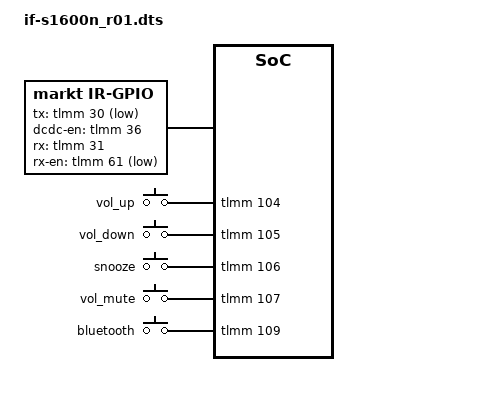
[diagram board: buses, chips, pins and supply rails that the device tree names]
/dts-v1/;

#include "if-s1600n_base.dtsi"

/ {
	markt,board-rev = <0x0001>;
};

&soc {
    ir-gpio {
       compatible = "markt,ir-gpio";
       tx-gpios = <&tlmm 30 GPIO_ACTIVE_LOW>;         
       dcdc-en-gpios = <&tlmm 36 GPIO_ACTIVE_HIGH>;

       rx-gpios = <&tlmm 31 GPIO_ACTIVE_HIGH>;
       rx-en-gpios = <&tlmm 61 GPIO_ACTIVE_LOW>;
       pinctrl-names = "default";
       pinctrl-0 = <&tlmm_ir_gpio_active>;
       status = "ok";
    };
};

&gpio_keys {
    vdd-supply = <&pms405_l12>;
    vdd-voltage = <3300000 3300000>;
    vdd-cureent = <15000>;
    
    vol_up {
        label = "vol_up";
        gpios = <&tlmm 104 GPIO_ACTIVE_HIGH>;
        linux,input-type = <1>;
        linux,code = <KEY_VOLUMEUP>;
        debounce-interval = <50>;
        gpio-key,wakeup;
    };    

    vol_down {
        label = "vol_down";
        gpios = <&tlmm 105 GPIO_ACTIVE_HIGH>;
        linux,input-type = <1>;
        linux,code = <KEY_VOLUMEDOWN>;
        debounce-interval = <50>;
        gpio-key,wakeup;
    };

    snooze {
        label = "snooze";
        gpios = <&tlmm 106 GPIO_ACTIVE_HIGH>;
        linux,input-type = <1>;
        linux,code = <256>;
        debounce-interval = <50>;
        gpio-key,wakeup;
    };

    vol_mute {
        label = "vol_mute";
        gpios = <&tlmm 107 GPIO_ACTIVE_HIGH>;
        linux,input-type = <1>;
        linux,code = <KEY_MUTE>;
        debounce-interval = <50>;
        gpio-key,wakeup;
    };

    bluetooth {
        label = "bluetooth";
        gpios = <&tlmm 109 GPIO_ACTIVE_HIGH>;
        linux,input-type = <1>;
        linux,code = <257>;
        debounce-interval = <50>;
        gpio-key,wakeup;
    };

};


&tlmm {
	evb_tlmm_gpio_key{
		tlmm_gpio_key_active: tlmm_gpio_key_active {
			mux {
				pins = "gpio104", "gpio105", "gpio106", "gpio107", "gpio109";
			};

			config {
				pins = "gpio104", "gpio105", "gpio106", "gpio107", "gpio109";
			drive-strength = <2>;
			bias-disable;
			};
		};

		tlmm_gpio_key_suspend: tlmm_gpio_key_suspend {
			mux {
				pins = "gpio104", "gpio105", "gpio106", "gpio107", "gpio109";
			};

			config {
				pins = "gpio104", "gpio105", "gpio106", "gpio107", "gpio109";
			drive-strength = <2>;
			bias-disable;
			};
		};
	};

	tlmm_ir_gpio {
			tlmm_ir_gpio_active: tlmm_ir_gpio_active {
				mux {
					pins = "gpio31";
					function = "gpio";
				};
				
				config {
					pins = "gpio31";
					drive-strength = <2>;
					bias-disable;
				};
			};
			tlmm_ir_gpio_sleep: tlmm_ir_gpio_sleep {
				mux {
					pins = "gpio31";
					function = "gpio";
				};
				
				config {
					pins = "gpio31";
					drive-strength = <2>;
					bias-disable;
				};
			};
		};
	
};
